# a34g43x register map
Vendor: ABOV Semiconductor Co., Ltd.; File version: 1.0
CPU: CM4 r0p1, little endian, MPU, FPU, VTOR, 4 interrupt priority bits
Registers are 32-bit, read-write, reset 0x0 unless marked. A register's access mark holds for its fields unless they carry their own. Offsets are from the block's base; [hi:lo] are bit positions; {n}, {i} and the like mark numbered series; 'fields as' and 'values as' point back to an identical list.

## ADC — 12-BIT A/D CONVERTER
Base 0x51012000
Same registers: ADC0 0x41012000, ADC1 0x41012100, ADC2 0x41012200
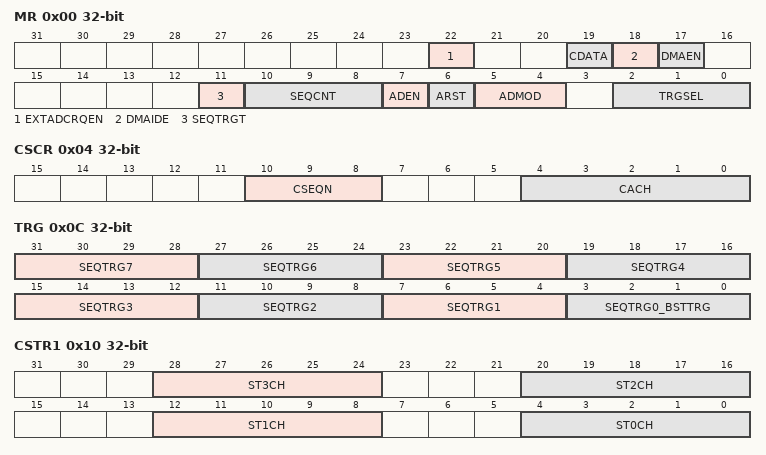
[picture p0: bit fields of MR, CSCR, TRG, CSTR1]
0x00 MR — ADC Mode Register
  [22] EXTADCRQEN — Conversion start control request bit from another external ADC
    0=Disable; 1=Enable
  [19] CDATA — Conversion data offset alignment
    0=Offset_4thbit ([15:4] offset alignment); 1=Offset_0thbit ([11:0] offset alignment)
  [18] DMAIDE — Whether the DMA includes the injection data
    0=NOT_Include (Does not include.); 1=Includes
  [17] DMAEN — DMA Enable Bit (only ADCEN=1)
    0=Disable (DMA Disable); 1=Enable (DMA Enable)
  [11] SEQTRGT — Trigger pending type control in sequential mode
    0=Not_pending (Trigger that is not related current count in sequential is not pending.); 1=Pending (Trigger that is not related current count in sequential is pending)
  [10:8] SEQCNT — Number of conversion in a sequence
    0=Single_Mode; {v}={v+1}_Sequence_ADC (v=1..7)
  [7] ADEN — ADC Enable Bit
    0=Disable ADC; 1=Enable ADC
  [6] ARST — When sequence is over, restart control bit
    0=STOP (after ending, STOP); 1=RESTART (After ending, restart)
  [5:4] ADMOD — ADC Mode Selection Bit
    0=Single_Sequencial Conversion Mode; 1=Burst Conversion Mode; 2=Multiple Conversion Mode
  [2:0] TRGSEL — Trigger Selection Bit
    0=Soft_TRG (Software Trigger Only); 1=TIMER (TIMER event trigger); 2=MPWM0 (MPWM0 Event Trigger); 3=MPWM1 (MPWM1 Event Trigger)
0x04 CSCR — ADC Current Sequence_Channel Register
  [10:8] CSEQN — Current Sequence Number
    {v}=Sequence{v} (Current Sequence {v}) (v=0..7)
  [4:0] CACH ro — Current Active Channel
    {v}=CH{v} (ADC Channel active is {v}) (v=0..23)
0x08 CCR reset 0x80 — ADC Clock Control Register
  [14:8] CLKDIV — ADC Clock Divider value bit, ADC CLK = ADC Input Clock / CLKDIV (CLKDIV=1 ADC Stop, CLKDIV=0 ADC Input Clock)
0x0C TRG — ADC Trigger Selection Register
  [all] fields
    {v}=Source_{v} (v=0..9); 15=Source_15
  [4n+3:4n] SEQTRG{n} (n=1..7) — Sequence Trigger Source {n+1}th
  [3:0] SEQTRG0_BSTTRG — Sequence Trigger Source 1th, Burst Conversion Trigger Source
0x10 CSTR1 — ADC0 channel sampling time 1 register
  [28:24] ST3CH — 4th conversion sequence channel sampling time
  [20:16] ST2CH — 3rd conversion sequence channel sampling time
  [12:8] ST1CH — 2nd conversion sequence channel sampling time
  [4:0] ST0CH — 1st conversion sequence channel sampling time
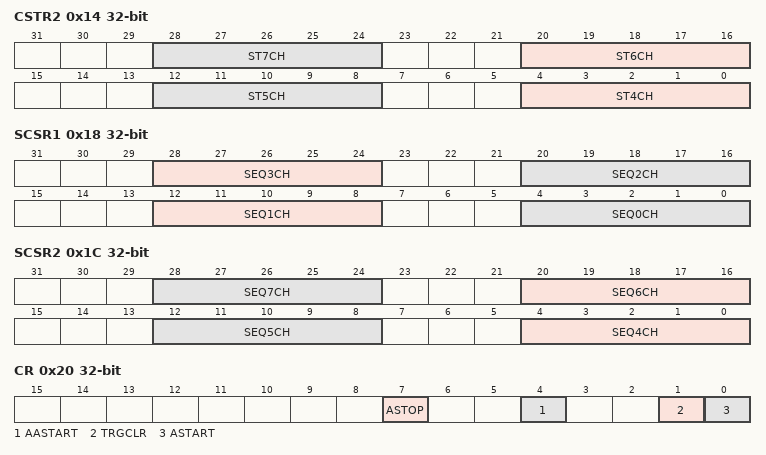
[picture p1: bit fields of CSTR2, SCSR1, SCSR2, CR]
0x14 CSTR2 — ADC0 channel sampling time 2 register
  [8n-28:8n-32] ST{n}CH (n=4..7) — {n+1}th conversion sequence channel sampling time
0x18 SCSR1 — ADC Channel Selection Register 1
  [28:24] SEQ3CH — Conversion Sequence Channel Selection 4th
  [20:16] SEQ2CH — Conversion Sequence Channel Selection 3rd
  [12:8] SEQ1CH — Conversion Sequence Channel Selection 2nd
  [4:0] SEQ0CH — Conversion Sequence Channel Selection 1st
0x1C SCSR2 — ADC Channel Selection Register 2
  [8n-28:8n-32] SEQ{n}CH (n=4..7) — Conversion Sequence Channel Selection {n+1}th
0x20 CR — ADC Control Register
  [7] ASTOP wo — ADC STOP bit
  [4] AASTART — All ADC START bit
  [1] TRGCLR — ADC all trigger flags cleared option (previous ADC operation)
  [0] ASTART — ADC START Bit
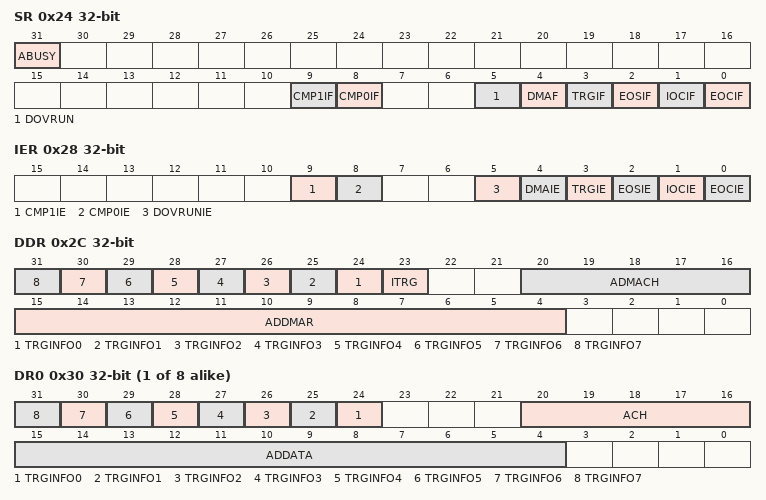
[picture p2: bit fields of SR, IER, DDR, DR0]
0x24 SR — ADC Status Register
  [31] ABUSY ro — ADC busy status
    0=Not_busy; 1=Busy
  [9] CMP1IF — Compare 1 interrupt flag bit
    0=Not_generated (Interrupt not generated); 1=Generated (Interrupt is generated (Writing 1 clears the flag))
  [8] CMP0IF — Compare 0 interrupt flag bit
    values as CMP1IF
  [5] DOVRUN ro — DMA Overrun Flag (Not Interrupt)
  [4] DMAF ro — DMA Done Received Flag (DMA transfer is completed)
  [3] TRGIF — ADC Trigger Interrupt Flag (Write '1' to clear flag)
  [2] EOSIF — Sequence End Interrupt Flag (Write '1' to clear flag)
  [1] IOCIF — Injection conversion end interrupt flag (Write '1' to clear flag)
  [0] EOCIF — Sequence Conversion End Interrupt Flag (Write '1' to clear flag)
0x28 IER — ADC Interrupt Enable Register
  [9] CMP1IE — Compare 1 event interrupt enable
    0=Disable (Compare 1 Interrupt Disable); 1=Enable (Compare 1 Interrupt Enable)
  [8] CMP0IE — Compare 0 event interrupt enable
    0=Disable (Compare 0 Interrupt Disable); 1=Enable (Compare 0 Interrupt Enable)
  [5] DOVRUNIE — DMA Overrun Interrupt Enable
    0=Disable (DMA Overrun Interrupt Disable); 1=Enable (DMA Overrun Interrupt Enable)
  [4] DMAIE — DMA Done Interrupt Enable
    0=Disable (DMA Done Interrupt Disable); 1=Enable (DMA Done Interrupt Enable)
  [3] TRGIE — ADC Trigger Conversion Interrupt Enable
    0=Disable (ADC Trigger Conversion Interrupt Disable); 1=Enable (ADC Trigger Conversion Interrupt Enable)
  [2] EOSIE — ADC Sequence Conversion Interrupt Enable
    0=Disable (ADC Sequence Conversion Interrupt Disable); 1=Enable (ADC Sequence Conversion Interrupt Enable)
  [1] IOCIE — ADC Injection Conversion Interrupt Enable
    0=Disable (ADC Injection Conversion Interrupt Disable); 1=Enable (ADC Injection Conversion Interrupt Enable)
  [0] EOCIE — ADC Single Conversion Interrupt Enable
    0=Disable (ADC Single Conversion Interrupt Disable); 1=Enable (ADC Single Conversion Interrupt Enable)
0x2C DDR ro — ADC DMA Data Register
  [n+24] TRGINFO{n} (n=0..7) — ADC Trigger Information {n}
  [23] ITRG — ADC Injected mode Trigger Information
  [20:16] ADMACH — ADC Data Channel Indicator
  [15:4] ADDMAR — ADC Conversion Result Data (12-bit)
{0x30+4i} DR{i} (i=0..7) — ADC Sequence Data Register{i}
  [n+24] TRGINFO{n} ro (n=0..7) — ADC Trigger Information {n}
  [20:16] ACH ro — ADC Channel Information
  [15:4] ADDATA ro — ADC Channel Data (12-bit)
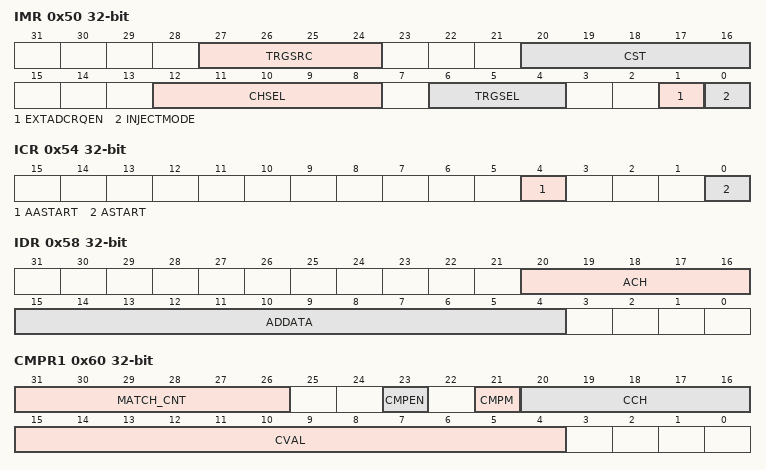
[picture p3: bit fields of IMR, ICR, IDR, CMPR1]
0x50 IMR — ADC injection mode register
  [27:24] TRGSRC — ADC Trigger source selection bit
  [20:16] CST — ADC Channel sampling time
  [12:8] CHSEL — ADC Channel selection
  [6:4] TRGSEL — ADC Trigger selection bit
    0=Event_Trigger_disable (ADC Event trigger disable / Soft trigger only); 1=Timer (ADC Timer event trigger / Soft trigger); 2=MPWM0 (ADC MPWM0 event trigger / Soft trigger); 3=MPWM1 (ADC MPWM1 event trigger / Soft trigger)
  [1] EXTADCRQEN — Conversion start control request bit from another external ADC
    0=Disable; 1=Enable
  [0] INJECTMODE — Injection conversion mode enable bit
    0=Disable; 1=Enable
0x54 ICR — ADC injection control register
  [4] AASTART — All ADC START bit
    0=Stop (No effect); 1=Start (All ADC Conversion start)
  [0] ASTART — ADC START bit
    0=Stop (No ADC conversion); 1=Starts ADC conversion.To start ADC conversion, the ADEN bit must be set to 1
0x58 IDR — ADC injection Data register
  [20:16] ACH ro — Injection ADC channel information
  [15:4] ADDATA ro — Injection ADC input data
0x60 CMPR1 — ADC Channel Compare Register 1
  [31:26] MATCH_CNT — Interrupt is generated only when ADC data compare data meets the condition
  [23] CMPEN — Compare Operation Enable Bit
    0=Disable (Compare Disable); 1=Enable (Compare Enable)
  [21] CMPM — ADC compare mode bit/description
    0=High_thanCVAL (ADC value is higher than CVAL[11:0] value.); 1=Low_thanCVAL (ADC value is lower than CVAL[11:0] value.)
  [20:16] CCH — Compare Channel
    {v}=CH{v} (ADC Channel {v}) (v=0..23)
  [15:4] CVAL — Compare Value
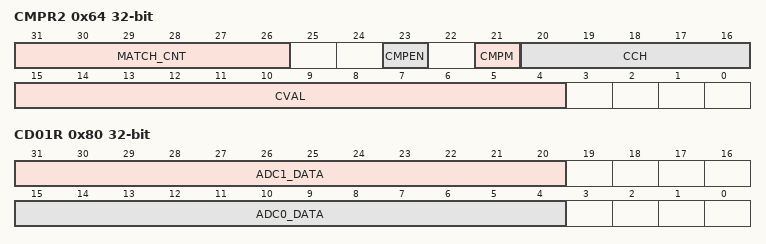
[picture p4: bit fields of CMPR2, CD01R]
0x64 CMPR2 — ADC Channel Compare Register 2
  fields as CMPR1
0x80 CD01R ro — ADC 0, 1 Data Register
  [31:20] ADC1_DATA — ADC1 conversion result data (12-bit)
  [15:4] ADC0_DATA — ADC0 conversion result data (12-bit)
0x84 CD2R ro — ADC 2 Data Register
  [15:4] ADC2_DATA — ADC2 conversion result data (12-bit)
